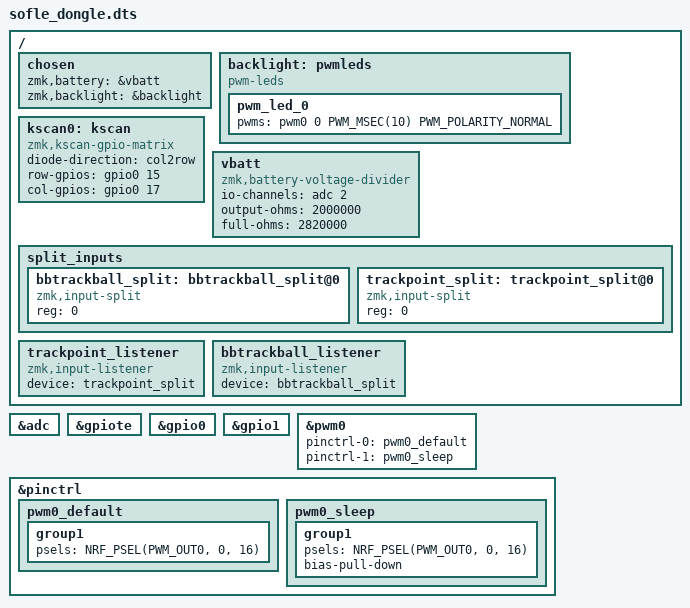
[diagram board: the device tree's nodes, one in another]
/*
 * Copyright (c) 2023 ZitaoTech
 *
 * SPDX-License-Identifier: MIT
 */

#include "sofle_dongle.dtsi"
#include <input/processors.dtsi>
#include <zephyr/dt-bindings/input/input-event-codes.h>
#include <dt-bindings/zmk/keys.h>

/ {
    chosen {
        zmk,battery = &vbatt;
        zmk,backlight = &backlight;
    };

    backlight: pwmleds {
        compatible = "pwm-leds";
        pwm_led_0 {
            pwms = <&pwm0 0 PWM_MSEC(10) PWM_POLARITY_NORMAL>;
        };
    };

    kscan0: kscan {
        compatible = "zmk,kscan-gpio-matrix";
        diode-direction = "col2row";
        row-gpios
            = <&gpio0 15 (GPIO_ACTIVE_HIGH | GPIO_PULL_DOWN)>
            ;
        col-gpios
            = <&gpio0 17  GPIO_ACTIVE_HIGH>
            ;
    };


    vbatt: vbatt {
        compatible = "zmk,battery-voltage-divider";
        io-channels = <&adc 2>;
        output-ohms = <2000000>;
        full-ohms = <2820000>;  // 2000000 + 820000
    };
};


/ {
    split_inputs {
        #address-cells = <1>;
        #size-cells = <0>;

        bbtrackball_split: bbtrackball_split@0 {
            compatible = "zmk,input-split";
            reg = <0>;
        };
    };

};


/ {
    split_inputs {
        #address-cells = <1>;
        #size-cells = <0>;

        trackpoint_split: trackpoint_split@0 {
            compatible = "zmk,input-split";
            reg = <0>;
        };
    };

};


/ {
    trackpoint_listener: trackpoint_listener {
        compatible = "zmk,input-listener";
        status = "disabled";
        device = <&trackpoint_split>;
    };
    bbtrackball_listener: bbtrackball_listener {
        compatible = "zmk,input-listener";
        status = "disabled";
        device = <&bbtrackball_split>;
    };
};

&trackpoint_listener {
    status = "okay";
};

&bbtrackball_listener {
    status = "okay";
};

&adc {
    status = "okay";
};

&gpiote {
    status = "okay";
};

&gpio0 {
    status = "okay";
};

&gpio1 {
    status = "okay";
};

&pwm0 {
    status = "okay";
    pinctrl-0 = <&pwm0_default>;
    pinctrl-1 = <&pwm0_sleep>;
    pinctrl-names = "default", "sleep";
};




&pinctrl {

    pwm0_default:pwm0_default{
        group1{
            psels = <NRF_PSEL(PWM_OUT0, 0, 16)>; // Backlight for backlight.c unreal
        };
    };

    pwm0_sleep: pwm0_sleep {
        group1 {
            psels = <NRF_PSEL(PWM_OUT0, 0, 16)>;
            bias-pull-down;
        };
    };

};

/*
/ {
    input_processors {
        zip_right_click_trigger_paste: zip_right_click_trigger_paste {
            compatible = "zmk,input-processor-behaviors";
            #input-processor-cells = <0>;
            codes    = <INPUT_BTN_1>;
            bindings = <&kp A>;
        };
    };
}; */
